AUTOSAR XML (schema 00050)
package /AUTOSAR/AISpecification/SwComponentTypes_Blueprint/SnsrActrAbstraction
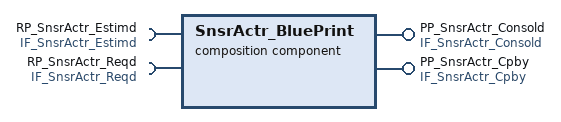
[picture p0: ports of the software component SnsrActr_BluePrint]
  composition sw component type SnsrActr_BluePrint
    provide port PP_SnsrActr_Consold: provided-interface=IF_SnsrActr_Consold
    provide port PP_SnsrActr_Cpby: provided-interface=IF_SnsrActr_Cpby
    require port RP_SnsrActr_Estimd: required-interface=IF_SnsrActr_Estimd
    require port RP_SnsrActr_Reqd: required-interface=IF_SnsrActr_Reqd
    6 x component:
      CPT_SnsrActr_DevCoorrVirt: type=SnsrActr_DevCoorrVirt
      CPT_SnsrActr_DevDrvrActr: type=SnsrActr_DevDrvrActr
      CPT_SnsrActr_DevDrvrSnsr: type=SnsrActr_DevDrvrSnsr
      CPT_SnsrActr_DevSnsrVirt: type=SnsrActr_DevSnsrVirt
      CPT_SnsrActr_DrvrActrElec: type=SnsrActr_DrvrActrElec
      CPT_SnsrActr_DrvrSnsrElec: type=SnsrActr_DrvrSnsrElec
    connect CPT_SnsrActr_DevSnsrVirt.PP_SnsrActr_DevSnsrVirt_Consold -> CPT_SnsrActr_DevDrvrActr.RP_SnsrActr_DevDrvrActr_Consold
    connect CPT_SnsrActr_DrvrSnsrElec.PP_SnsrActr_DrvrSnsrElec_ElecBascFild -> CPT_SnsrActr_DevDrvrSnsr.RP_SnsrActr_DevDrvrSnsr_ElecBascFild
    connect CPT_SnsrActr_DrvrSnsrElec.PP_SnsrActr_DrvrSnsrElec_ElecRaw -> CPT_SnsrActr_DevDrvrSnsr.RP_SnsrActr_DevDrvrSnsr_ElecRaw
    connect CPT_SnsrActr_DevDrvrSnsr.PP_SnsrActr_DevDrvrSnsr_Measd -> CPT_SnsrActr_DevSnsrVirt.RP_SnsrActr_DevSnsrVirt_Measd
    connect CPT_SnsrActr_DevDrvrActr.PP_SnsrActr_DevDrvrActr_Outp -> CPT_SnsrActr_DrvrActrElec.RP_SnsrActr_DrvrActrElec_Outp
    connect CPT_SnsrActr_DevDrvrSnsr.PP_SnsrActr_DevDrvrSnsr_Raw -> CPT_SnsrActr_DevSnsrVirt.RP_SnsrActr_DevSnsrVirt_Raw
    connect CPT_SnsrActr_DevCoorrVirt.PP_SnsrActr_DevCoorrVirt_Sp -> CPT_SnsrActr_DevDrvrActr.RP_SnsrActr_DevDrvrActr_Sp
    delegate CPT_SnsrActr_DevSnsrVirt.PP_SnsrActr_DevSnsrVirt_Consold <-> outer port PP_SnsrActr_Consold
    delegate CPT_SnsrActr_DevDrvrActr.PP_SnsrActr_DevDrvrActr_Cpby <-> outer port PP_SnsrActr_Cpby
    delegate CPT_SnsrActr_DevSnsrVirt.RP_SnsrActr_DevSnsrVirt_Estimd <-> outer port RP_SnsrActr_Estimd
    delegate CPT_SnsrActr_DevCoorrVirt.RP_SnsrActr_DevCoorrVirt_Reqd <-> outer port RP_SnsrActr_Reqd
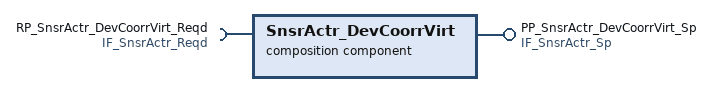
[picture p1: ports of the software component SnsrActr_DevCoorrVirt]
  composition sw component type SnsrActr_DevCoorrVirt
    provide port PP_SnsrActr_DevCoorrVirt_Sp: provided-interface=IF_SnsrActr_Sp
    require port RP_SnsrActr_DevCoorrVirt_Reqd: required-interface=IF_SnsrActr_Reqd
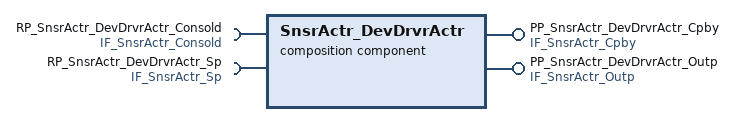
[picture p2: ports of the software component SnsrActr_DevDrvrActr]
  composition sw component type SnsrActr_DevDrvrActr
    provide port PP_SnsrActr_DevDrvrActr_Cpby: provided-interface=IF_SnsrActr_Cpby
    provide port PP_SnsrActr_DevDrvrActr_Outp: provided-interface=IF_SnsrActr_Outp
    require port RP_SnsrActr_DevDrvrActr_Consold: required-interface=IF_SnsrActr_Consold
    require port RP_SnsrActr_DevDrvrActr_Sp: required-interface=IF_SnsrActr_Sp
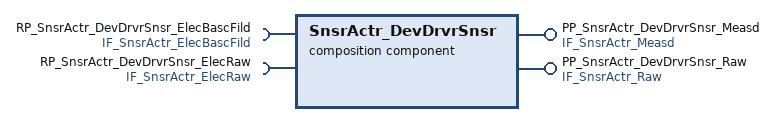
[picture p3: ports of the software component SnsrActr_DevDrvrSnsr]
  composition sw component type SnsrActr_DevDrvrSnsr
    provide port PP_SnsrActr_DevDrvrSnsr_Measd: provided-interface=IF_SnsrActr_Measd
    provide port PP_SnsrActr_DevDrvrSnsr_Raw: provided-interface=IF_SnsrActr_Raw
    require port RP_SnsrActr_DevDrvrSnsr_ElecBascFild: required-interface=IF_SnsrActr_ElecBascFild
    require port RP_SnsrActr_DevDrvrSnsr_ElecRaw: required-interface=IF_SnsrActr_ElecRaw
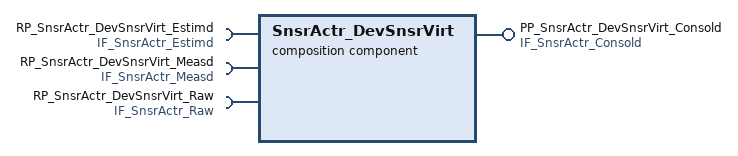
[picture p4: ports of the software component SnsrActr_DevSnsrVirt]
  composition sw component type SnsrActr_DevSnsrVirt
    provide port PP_SnsrActr_DevSnsrVirt_Consold: provided-interface=IF_SnsrActr_Consold
    require port RP_SnsrActr_DevSnsrVirt_Estimd: required-interface=IF_SnsrActr_Estimd
    require port RP_SnsrActr_DevSnsrVirt_Measd: required-interface=IF_SnsrActr_Measd
    require port RP_SnsrActr_DevSnsrVirt_Raw: required-interface=IF_SnsrActr_Raw
  composition sw component type SnsrActr_DrvrActrElec
    require port RP_SnsrActr_DrvrActrElec_Outp: required-interface=IF_SnsrActr_Outp
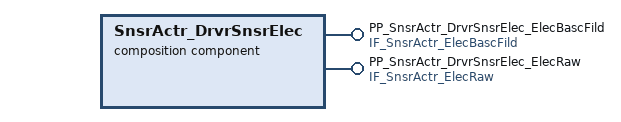
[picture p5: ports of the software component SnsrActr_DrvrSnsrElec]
  composition sw component type SnsrActr_DrvrSnsrElec
    provide port PP_SnsrActr_DrvrSnsrElec_ElecBascFild: provided-interface=IF_SnsrActr_ElecBascFild
    provide port PP_SnsrActr_DrvrSnsrElec_ElecRaw: provided-interface=IF_SnsrActr_ElecRaw
package /AUTOSAR/AISpecification/SwComponentTypes_Blueprint/SnsrActrAbstraction/PortInterfaces
  10 x sender receiver interface:
    IF_SnsrActr_Consold
    IF_SnsrActr_Cpby
    IF_SnsrActr_ElecBascFild
    IF_SnsrActr_ElecRaw
    IF_SnsrActr_Estimd
    IF_SnsrActr_Measd
    IF_SnsrActr_Outp
    IF_SnsrActr_Raw
    IF_SnsrActr_Reqd
    IF_SnsrActr_Sp
